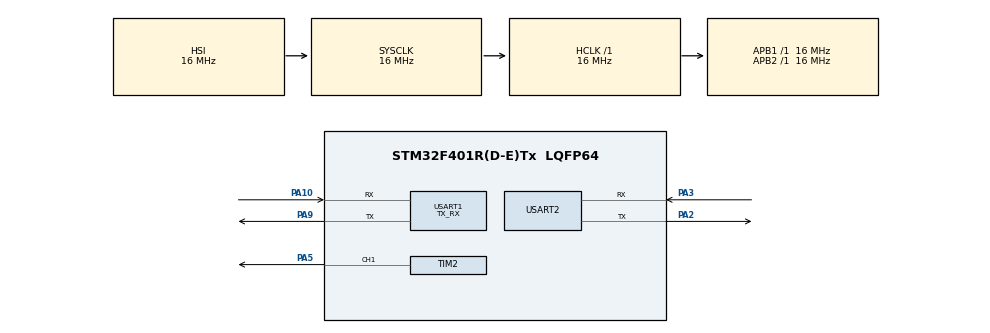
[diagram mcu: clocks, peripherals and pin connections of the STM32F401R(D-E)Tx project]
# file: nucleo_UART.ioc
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Mcu.Family=STM32F4
Mcu.Name=STM32F401R(D-E)Tx
Mcu.Package=LQFP64
NVIC.PriorityGroup=NVIC_PRIORITYGROUP_4
PA10.Mode=Asynchronous
PA10.Signal=USART1_RX
PA2.Mode=Asynchronous
PA2.Signal=USART2_TX
PA3.Mode=Asynchronous
PA3.Signal=USART2_RX
PA5.Signal=S_TIM2_CH1_ETR
PA9.Mode=Asynchronous
PA9.Signal=USART1_TX
PH0\ -\ OSC_IN.Mode=HSE-External-Clock-Source
PH0\ -\ OSC_IN.Signal=RCC_OSC_IN
PH1\ -\ OSC_OUT.Mode=HSE-External-Clock-Source
PH1\ -\ OSC_OUT.Signal=RCC_OSC_OUT
ProjectManager.HeapSize=0x200
ProjectManager.StackSize=0x400
ProjectManager.TargetToolchain=STM32CubeIDE
RCC.AHBFreq_Value=16000000
RCC.APB1Freq_Value=16000000
RCC.APB1TimFreq_Value=16000000
RCC.APB2Freq_Value=16000000
RCC.APB2TimFreq_Value=16000000
RCC.CortexFreq_Value=16000000
RCC.HCLKFreq_Value=16000000
RCC.HSE_VALUE=25000000
RCC.HSI_VALUE=16000000
RCC.LSE_VALUE=32768
RCC.SYSCLKFreq_VALUE=16000000
RCC.VCOOutputFreq_Value=192000000
SH.S_TIM2_CH1_ETR.0=TIM2_CH1,PWM Generation1 CH1
TIM2.Channel-PWM\ Generation1\ CH1=TIM_CHANNEL_1
TIM2.Period=100
TIM2.Prescaler=16
USART1.Mode=MODE_TX_RX
USART1.VirtualMode=VM_ASYNC
USART2.VirtualMode=VM_ASYNC
board=custom

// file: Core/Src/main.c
/* USER CODE BEGIN Header */
/**
  ******************************************************************************
  * @file           : main.c
  * @brief          : Main program body
  ******************************************************************************
  * @attention
  *
  * Copyright (c) 2024 STMicroelectronics.
  * All rights reserved.
  *
  * This software is licensed under terms that can be found in the LICENSE file
  * in the root directory of this software component.
  * If no LICENSE file comes with this software, it is provided AS-IS.
  *
  ******************************************************************************
  */
/* USER CODE END Header */
#include "main.h"

TIM_HandleTypeDef htim2;

UART_HandleTypeDef huart1;
UART_HandleTypeDef huart2;

/* USER CODE BEGIN PV */
uint8_t hi[10] = "nucleo\n\r";
uint8_t hex[2] = {0x8, 0x8}; // can't see that on the terminal
uint8_t echo[3] = {0x1, 0x3, 0x9};
/* USER CODE END PV */

void SystemClock_Config(void);
static void MX_GPIO_Init(void);
static void MX_USART2_UART_Init(void);
static void MX_USART1_UART_Init(void);
static void MX_TIM2_Init(void);
/* USER CODE BEGIN PFP */

void serial_print(uint8_t data[], uint8_t size);

/* USER CODE END PFP */

int main(void)
{

  /* USER CODE BEGIN 1 */

  uint8_t duty = 10;
  /* USER CODE END 1 */

  /* MCU Configuration--------------------------------------------------------*/

  /* Reset of all peripherals, Initializes the Flash interface and the Systick. */
  HAL_Init();

  /* Configure the system clock */
  SystemClock_Config();

  /* Initialize all configured peripherals */
  MX_GPIO_Init();
  MX_USART2_UART_Init();
  MX_USART1_UART_Init();
  MX_TIM2_Init();
  /* USER CODE BEGIN 2 */

  TIM2->CCR1 = duty;
  HAL_TIM_PWM_Start(&htim2, TIM_CHANNEL_1);

  //HAL_UART_Receive_IT(&huart1, echo, 10);

  /* USER CODE END 2 */

  /* Infinite loop */
  /* USER CODE BEGIN WHILE */
  while (1)
  {
	  // echo program
	  // HAL_UART_Receive(&huart1, echo, sizeof(echo), 10);
	  // HAL_UART_Transmit(&huart2, echo, sizeof(echo), 10);

	  // receive & send duty
	  HAL_UART_Receive(&huart2, &duty, 1, 20);
	  HAL_UART_Transmit(&huart1, &duty, 1, 20);

	  // LED duty sync
	  TIM2->CCR1 = duty;

    /* USER CODE END WHILE */

  }
}

void SystemClock_Config(void)
{
  RCC_OscInitTypeDef RCC_OscInitStruct = {0};
  RCC_ClkInitTypeDef RCC_ClkInitStruct = {0};

  /** Configure the main internal regulator output voltage
  */
  __HAL_RCC_PWR_CLK_ENABLE();
  __HAL_PWR_VOLTAGESCALING_CONFIG(PWR_REGULATOR_VOLTAGE_SCALE2);

  /** Initializes the RCC Oscillators according to the specified parameters
  * in the RCC_OscInitTypeDef structure.
  */
  RCC_OscInitStruct.OscillatorType = RCC_OSCILLATORTYPE_HSI;
  RCC_OscInitStruct.HSIState = RCC_HSI_ON;
  RCC_OscInitStruct.HSICalibrationValue = RCC_HSICALIBRATION_DEFAULT;
  RCC_OscInitStruct.PLL.PLLState = RCC_PLL_NONE;
  if (HAL_RCC_OscConfig(&RCC_OscInitStruct) != HAL_OK)
  {
    Error_Handler();
  }

  /** Initializes the CPU, AHB and APB buses clocks
  */
  RCC_ClkInitStruct.ClockType = RCC_CLOCKTYPE_HCLK|RCC_CLOCKTYPE_SYSCLK
                              |RCC_CLOCKTYPE_PCLK1|RCC_CLOCKTYPE_PCLK2;
  RCC_ClkInitStruct.SYSCLKSource = RCC_SYSCLKSOURCE_HSI;
  RCC_ClkInitStruct.AHBCLKDivider = RCC_SYSCLK_DIV1;
  RCC_ClkInitStruct.APB1CLKDivider = RCC_HCLK_DIV1;
  RCC_ClkInitStruct.APB2CLKDivider = RCC_HCLK_DIV1;

  if (HAL_RCC_ClockConfig(&RCC_ClkInitStruct, FLASH_LATENCY_0) != HAL_OK)
  {
    Error_Handler();
  }
}

static void MX_TIM2_Init(void)
{

  TIM_MasterConfigTypeDef sMasterConfig = {0};
  TIM_OC_InitTypeDef sConfigOC = {0};

  htim2.Instance = TIM2;
  htim2.Init.Prescaler = 16;
  htim2.Init.CounterMode = TIM_COUNTERMODE_UP;
  htim2.Init.Period = 100;
  htim2.Init.ClockDivision = TIM_CLOCKDIVISION_DIV1;
  htim2.Init.AutoReloadPreload = TIM_AUTORELOAD_PRELOAD_DISABLE;
  if (HAL_TIM_PWM_Init(&htim2) != HAL_OK)
  {
    Error_Handler();
  }
  sMasterConfig.MasterOutputTrigger = TIM_TRGO_RESET;
  sMasterConfig.MasterSlaveMode = TIM_MASTERSLAVEMODE_DISABLE;
  if (HAL_TIMEx_MasterConfigSynchronization(&htim2, &sMasterConfig) != HAL_OK)
  {
    Error_Handler();
  }
  sConfigOC.OCMode = TIM_OCMODE_PWM1;
  sConfigOC.Pulse = 0;
  sConfigOC.OCPolarity = TIM_OCPOLARITY_HIGH;
  sConfigOC.OCFastMode = TIM_OCFAST_DISABLE;
  if (HAL_TIM_PWM_ConfigChannel(&htim2, &sConfigOC, TIM_CHANNEL_1) != HAL_OK)
  {
    Error_Handler();
  }
  HAL_TIM_MspPostInit(&htim2);

}

static void MX_USART1_UART_Init(void)
{

  huart1.Instance = USART1;
  huart1.Init.BaudRate = 115200;
  huart1.Init.WordLength = UART_WORDLENGTH_8B;
  huart1.Init.StopBits = UART_STOPBITS_1;
  huart1.Init.Parity = UART_PARITY_NONE;
  huart1.Init.Mode = UART_MODE_TX_RX;
  huart1.Init.HwFlowCtl = UART_HWCONTROL_NONE;
  huart1.Init.OverSampling = UART_OVERSAMPLING_16;
  if (HAL_UART_Init(&huart1) != HAL_OK)
  {
    Error_Handler();
  }

}

static void MX_USART2_UART_Init(void)
{

  huart2.Instance = USART2;
  huart2.Init.BaudRate = 115200;
  huart2.Init.WordLength = UART_WORDLENGTH_8B;
  huart2.Init.StopBits = UART_STOPBITS_1;
  huart2.Init.Parity = UART_PARITY_NONE;
  huart2.Init.Mode = UART_MODE_TX_RX;
  huart2.Init.HwFlowCtl = UART_HWCONTROL_NONE;
  huart2.Init.OverSampling = UART_OVERSAMPLING_16;
  if (HAL_UART_Init(&huart2) != HAL_OK)
  {
    Error_Handler();
  }

}

static void MX_GPIO_Init(void)
{

  /* GPIO Ports Clock Enable */
  __HAL_RCC_GPIOH_CLK_ENABLE();
  __HAL_RCC_GPIOA_CLK_ENABLE();

}

/* USER CODE BEGIN 4 */
//void HAL_UART_RxCpltCallback(UART_HandleTypeDef *huart)
//{
  /* Prevent unused argument(s) compilation warning */
  //UNUSED(huart);

  // echos imput
  //HAL_UART_Transmit(&huart2, echo, 10, 10);
  //HAL_GPIO_TogglePin(GPIOA, GPIO_PIN_5);
  //HAL_Delay(300);

  //// restart reception
  //HAL_UART_Receive_IT(&huart1, echo, 10);
//}

void serial_print(uint8_t data[], uint8_t size){
	HAL_UART_Transmit(&huart2, data, size, 10);
}

/* USER CODE END 4 */

void Error_Handler(void)
{
  __disable_irq();
  while (1)
  {
  }
}
